VERSION "3.06 v1"

NS_ :

BS_:

BU_:

BO_ 3221225472 VECTOR__INDEPENDENT_SIG_MSG: 0 Vector__XXX
 SG_ EffectParametersRequest_Mux : 0|8@1+ (1,0) [0|0] "" Vector__XXX

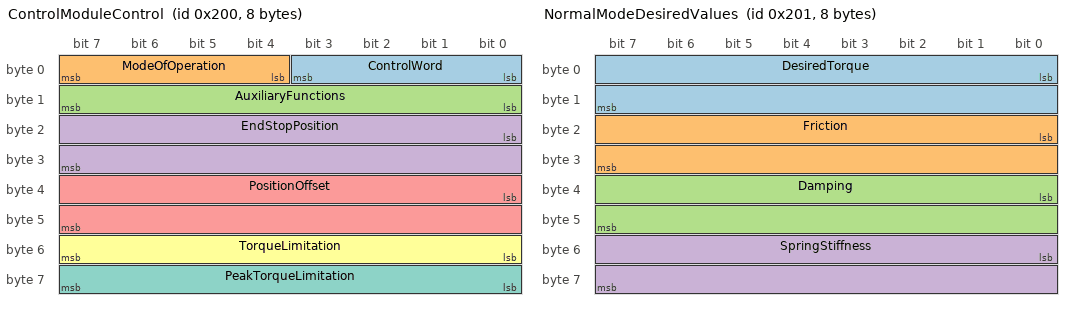
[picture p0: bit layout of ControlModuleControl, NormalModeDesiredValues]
BO_ 512 ControlModuleControl: 8 Vector__XXX
 SG_ ControlWord : 0|4@1+ (1,0) [0|15] "" Vector__XXX
 SG_ ModeOfOperation : 4|4@1+ (1,0) [1|8] "" Vector__XXX
 SG_ AuxiliaryFunctions : 8|8@1+ (1,0) [0|255] "" Vector__XXX
 SG_ EndStopPosition : 16|16@1+ (1,0) [0|1440] "°" Vector__XXX
 SG_ PositionOffset : 32|16@1- (1,0) [-359|359] "°" Vector__XXX
 SG_ TorqueLimitation : 48|8@1+ (1,0) [0|255] "%" Vector__XXX
 SG_ PeakTorqueLimitation : 56|8@1+ (1,0) [0|100] "%" Vector__XXX

BO_ 513 NormalModeDesiredValues: 8 Vector__XXX
 SG_ DesiredTorque : 0|16@1- (0.001,0) [-32.768|32.767] "Nm" Vector__XXX
 SG_ Friction : 16|16@1+ (1,0) [0|5000] "mNm" Vector__XXX
 SG_ Damping : 32|16@1+ (1,0) [0|500] "mNm/rpm" Vector__XXX
 SG_ SpringStiffness : 48|16@1+ (1,0) [0|2500] "mNm/°" Vector__XXX

BO_ 514 BasicModeDesiredValues: 2 Vector__XXX
 SG_ DesiredTorque : 0|16@1- (0.001,0) [-32.768|32.767] "Nm" Vector__XXX

BO_ 522 DigitalOutputValues: 2 Vector__XXX
 SG_ DigitalOutput : 0|3@1+ (1,0) [0|7] "" Vector__XXX

BO_ 523 AbsolutePosition: 2 Vector__XXX
 SG_ AbsolutePosition : 0|16@1- (0.1,0) [-1440|1440] "°" Vector__XXX

BO_ 557 SystemParametersRequest: 1 Vector__XXX
 SG_ SystemParametersRequest_Mux M : 0|8@1+ (1,0) [0|0] "" Vector__XXX

BO_ 525 ReadOnlyValuesRequest: 1 Vector__XXX
 SG_ ReadOnlyValuesRequest_Mux M : 0|8@1+ (1,0) [0|0] "" Vector__XXX

BO_ 526 VersionRequest: 1 Vector__XXX
 SG_ VersionRequest_Mux M : 0|8@1+ (1,0) [0|0] "" Vector__XXX

BO_ 554 EffectParametersWrite: 8 Vector__XXX
 SG_ EffectParametersWrite_Mux M : 0|8@1+ (1,0) [0|0] "" Vector__XXX
 SG_ EffParaDesEndStopStiffness m1 : 16|16@1+ (1,0) [0|255] "mNm/°" Vector__XXX
 SG_ EffParaDesEndStopDamping m1 : 32|16@1+ (1,0) [0|65535] "mNm/rpm" Vector__XXX
 SG_ EffParaDesReferencingDamping m2 : 16|16@1+ (1,0) [0|255] "mNm/rpm" Vector__XXX
 SG_ EffParaDesFrictionGain m3 : 16|16@1+ (1,0) [0|255] "" Vector__XXX
 SG_ EffParaDesFrictionEdge m3 : 32|16@1+ (1,0) [0|65535] "mNm" Vector__XXX
 SG_ EffParaDesEndStopVibrationDist m4 : 16|16@1+ (1,0) [0|255] "°" Vector__XXX
 SG_ EffParaDesEndStopVibrationPeriod m4 : 32|16@1+ (1,0) [0|65535] "ms" Vector__XXX
 SG_ EffParaDesEndStopVibrationGap m4 : 48|16@1+ (1,0) [0|65535] "ms" Vector__XXX
 SG_ EffParaDesFriction2Damping m5 : 16|16@1+ (1,0) [0|255] "mNm/°" Vector__XXX
 SG_ EffParaDesFriction2Factor m5 : 32|16@1+ (0.01,0) [0|655.35] "%" Vector__XXX
 SG_ EffParaDesDampingHalfDampingVel m6 : 16|16@1+ (0.1,0) [0|25.5] "rpm" Vector__XXX
 SG_ EffParaDesDampingVelFilterConst m6 : 32|16@1+ (1,0) [0|65535] "" Vector__XXX
 SG_ TorqueScaling m7 : 16|16@1+ (0.1,0) [0|0.1] "" Vector__XXX

BO_ 545 UserParametersRequest: 1 Vector__XXX
 SG_ UserParametersRequest_Mux M : 0|8@1+ (1,0) [0|0] "" Vector__XXX

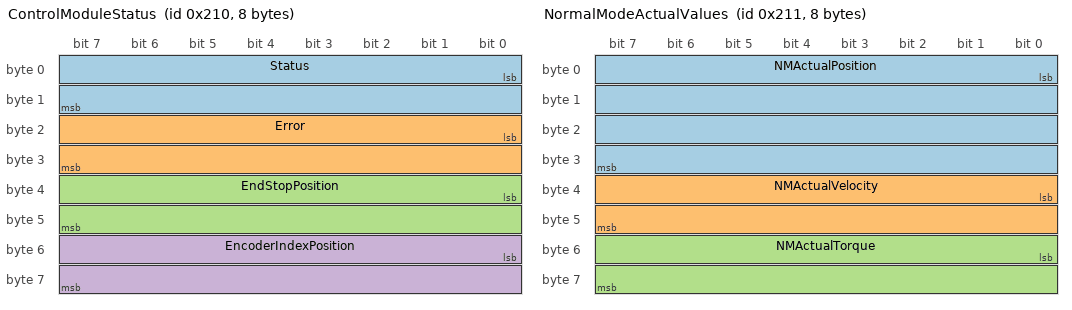
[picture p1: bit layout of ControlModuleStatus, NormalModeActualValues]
BO_ 528 ControlModuleStatus: 8 Vector__XXX
 SG_ Status : 0|16@1+ (1,0) [0|65535] "" Vector__XXX
 SG_ Error : 16|16@1+ (1,0) [0|65535] "" Vector__XXX
 SG_ EndStopPosition : 32|16@1+ (1,0) [0|1440] "°" Vector__XXX
 SG_ EncoderIndexPosition : 48|16@1- (1,0) [-359|359] "°" Vector__XXX

BO_ 529 NormalModeActualValues: 8 Vector__XXX
 SG_ NMActualPosition : 0|32@1- (1,0) [-2147483648|2147483647] "inc" Vector__XXX
 SG_ NMActualVelocity : 32|16@1- (1,0) [-32768|32767] "rpm" Vector__XXX
 SG_ NMActualTorque : 48|16@1- (0.001,0) [-32.768|32.767] "Nm" Vector__XXX

BO_ 530 BasicModeActualValues: 4 Vector__XXX
 SG_ BMActualPosition : 0|32@1- (1,0) [-2147483648|2147483647] "inc" Vector__XXX

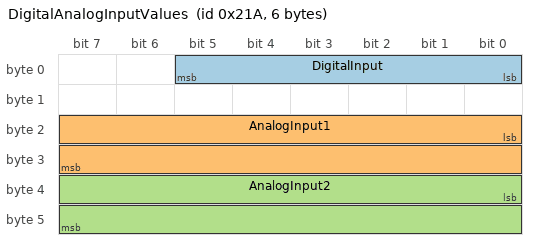
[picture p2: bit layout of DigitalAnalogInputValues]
BO_ 538 DigitalAnalogInputValues: 6 Vector__XXX
 SG_ DigitalInput : 0|6@1+ (1,0) [0|63] "" Vector__XXX
 SG_ AnalogInput1 : 16|16@1+ (1,0) [0|1023] "" Vector__XXX
 SG_ AnalogInput2 : 32|16@1+ (1,0) [0|1023] "" Vector__XXX

BO_ 539 AbsolutePositionResponse: 2 Vector__XXX
 SG_ AbsolutePosition : 0|16@1- (0.1,0) [-1440|1440] "°" Vector__XXX

BO_ 573 SystemParameters: 8 Vector__XXX
 SG_ SystemParameters_Mux M : 0|8@1+ (1,0) [0|0] "" Vector__XXX
 SG_ PositionIncrementsPerRevolution m1 : 16|32@1+ (1,0) [0|4294967295] "inc" Vector__XXX
 SG_ NominalTorque m2 : 16|16@1+ (0.001,0) [0|65.535] "Nm" Vector__XXX
 SG_ MaximumTorque m2 : 32|16@1+ (0.001,0) [0|65.535] "Nm" Vector__XXX

BO_ 541 ReadOnlyValues: 8 Vector__XXX
 SG_ ReadOnlyValues_Mux M : 0|8@1+ (1,0) [0|0] "" Vector__XXX
 SG_ TemperaturePowerStage m1 : 16|16@1+ (1,0) [0|65535] "°C" Vector__XXX
 SG_ TemperatureMicroprocessor m1 : 32|16@1+ (1,0) [0|65535] "°C" Vector__XXX
 SG_ TemperatureBreakChopper m1 : 48|16@1+ (1,0) [0|65535] "°C" Vector__XXX
 SG_ AverageAbsoluteMotorTorque m2 : 16|16@1+ (0.001,0) [0|65.535] "Nm" Vector__XXX
 SG_ Error m3 : 16|16@1+ (1,0) [0|65535] "" Vector__XXX
 SG_ HardwareSpecificError m3 : 32|16@1+ (1,0) [0|65535] "" Vector__XXX

BO_ 542 Version: 8 Vector__XXX
 SG_ Version_Mux M : 0|8@1+ (1,0) [0|0] "" Vector__XXX
 SG_ SoftwareBasicVersionMajor m1 : 24|8@1+ (1,0) [0|255] "" Vector__XXX
 SG_ SoftwareBasicVersionMinor m1 : 16|8@1+ (1,0) [0|255] "" Vector__XXX
 SG_ ProjectCode m1 : 32|16@1+ (1,0) [0|65535] "" Vector__XXX
 SG_ ProjectVersionMajor m1 : 56|8@1+ (1,0) [0|255] "" Vector__XXX
 SG_ ProjectVersionMinor m1 : 48|8@1+ (1,0) [0|255] "" Vector__XXX
 SG_ ProductCode m2 : 16|16@1+ (1,0) [0|65535] "" Vector__XXX
 SG_ HardwareOption m2 : 32|16@1+ (1,0) [0|65535] "" Vector__XXX

BO_ 570 EffectParameters: 8 Vector__XXX
 SG_ EffectParameters_Mux M : 0|8@1+ (1,0) [0|0] "" Vector__XXX
 SG_ EffParaEndStopStiffness m1 : 16|16@1+ (1,0) [0|65535] "mNm/°" Vector__XXX
 SG_ EffParaEndStopDamping m1 : 32|16@1+ (1,0) [0|65535] "mNm/rpm" Vector__XXX
 SG_ EffParaReferencingDamping m2 : 16|16@1+ (1,0) [0|65535] "mNm/rpm" Vector__XXX
 SG_ EffParaFrictionGain m3 : 16|16@1+ (1,0) [0|65535] "" Vector__XXX
 SG_ EffParaFrictionEdge m3 : 32|16@1+ (1,0) [0|65535] "mNm" Vector__XXX
 SG_ EffParaEndStopVibrationDist m4 : 16|16@1+ (1,0) [0|65535] "°" Vector__XXX
 SG_ EffParaEndStopVibrationPeriod m4 : 32|16@1+ (1,0) [0|65535] "ms" Vector__XXX
 SG_ EffParaEndStopVibrationGap m4 : 48|16@1+ (1,0) [0|65535] "ms" Vector__XXX
 SG_ EffParaFriction2Damping m5 : 16|16@1+ (1,0) [0|65535] "mNm/°" Vector__XXX
 SG_ EffParaFriction2Factor m5 : 32|16@1+ (0.01,0) [0|655.35] "%" Vector__XXX
 SG_ EffParaDampingHalfDampingVel m6 : 16|16@1+ (0.1,0) [0|6553.5] "rpm" Vector__XXX
 SG_ EffParaDampingVelFilterConst m6 : 32|16@1+ (1,0) [0|65535] "" Vector__XXX
 SG_ TorqueScaling m7 : 16|16@1+ (0.1,0) [10|100] "" Vector__XXX

BO_ 561 UserParameters: 8 Vector__XXX
 SG_ UserParameters_Mux M : 0|8@1+ (1,0) [0|0] "" Vector__XXX
 SG_ CANBaudRate : 16|32@1+ (1,0) [0|4294967295] "kBaud" Vector__XXX

CM_ BO_ 3221225472 "This is a message for not used signals, created by Vector CANdb++ DBC OLE DB Provider.";
CM_ BO_ 512 "Control Module ";
CM_ BO_ 513 "Normal Mode supporting full SENSO-Wheel features: Desired Values";
CM_ BO_ 514 "Basic Mode for fast communication: Desired Torque";
CM_ BO_ 522 "Digital output values (not SENSO-Wheel HT)";
CM_ BO_ 523 "Desired Absolute Position";
CM_ BO_ 557 "Request for System Parameters";
CM_ BO_ 525 "Request for Read-Only Values";
CM_ BO_ 526 "Request for Version and Product Information";
CM_ BO_ 554 "Write desired Effect ParametersRequest for Effect Parameters";
CM_ BO_ 545 "Request for User Parameters (firmware version 3.06 and newer)Write desired User Parameters (firmware version 3.06 and newer)";
CM_ BO_ 528 "Control Module";
CM_ BO_ 529 "Normal Mode supporting full SENSO-Wheel features: Actual Values";
CM_ BO_ 530 "Basic Mode for fast communication: Actual Position";
CM_ BO_ 538 "Digital and Analog Input Values (not SENSO-Wheel HT)";
CM_ BO_ 539 "Response to Desired Absolute Position";
CM_ BO_ 573 "System Parameters";
CM_ BO_ 541 "Read-Only Values";
CM_ BO_ 542 "Version and Product Information";
CM_ BO_ 570 "Effect Parameters";
CM_ BO_ 561 "User Parameters (firmware version 3.06 and newer)";
CM_ SG_ 561 UserParameters_Mux "CAN baud rate";
BA_DEF_  "BusType" STRING ;
BA_DEF_ BO_  "GenMsgCycleTime" INT 0 65535;
BA_DEF_ SG_  "GenSigStartValue" FLOAT -3.4E+038 3.4E+038;
BA_DEF_DEF_  "BusType" "CAN";
BA_DEF_DEF_  "GenMsgCycleTime" 0;
BA_DEF_DEF_  "GenSigStartValue" 0;
BA_ "GenMsgCycleTime" BO_ 512 10;
BA_ "GenMsgCycleTime" BO_ 513 1;
BA_ "GenMsgCycleTime" BO_ 514 1;
BA_ "GenSigStartValue" SG_ 512 ModeOfOperation 1;
BA_ "GenSigStartValue" SG_ 512 TorqueLimitation 100;
BA_ "GenSigStartValue" SG_ 512 PeakTorqueLimitation 100;
VAL_ 512 ControlWord 0 "SWITCH_OFF" 2 "SWITCH_READY" 4 "SWITCH_ON" 15 "QUIT_ERROR" ;
VAL_ 512 ModeOfOperation 1 "Normal Mode" 2 "Basic Mode" 4 "Referencing Mode" 8 "Demonstration Mode" ;
VAL_ 557 SystemParametersRequest_Mux 1 "DataSet1" 2 "DataSet2" ;
VAL_ 525 ReadOnlyValuesRequest_Mux 1 "DataSet1" 2 "DataSet2" 3 "DataSet3" ;
VAL_ 526 VersionRequest_Mux 1 "DataSet1" 2 "DataSet2" ;
VAL_ 554 EffectParametersWrite_Mux 1 "DataSet1" 2 "DataSet2" 3 "DataSet3" 4 "DataSet4" 5 "DataSet5" 6 "DataSet6" 7 "DataSet7" ;
VAL_ 545 UserParametersRequest_Mux 1 "Parameter1" ;
VAL_ 573 SystemParameters_Mux 1 "DataSet1" 2 "DataSet2" ;
VAL_ 541 ReadOnlyValues_Mux 1 "DataSet1" 2 "DataSet2" 3 "DataSet3" ;
VAL_ 542 Version_Mux 1 "DataSet1" 2 "DataSet2" ;
VAL_ 570 EffectParameters_Mux 1 "DataSet1" 2 "DataSet2" 3 "DataSet3" 4 "DataSet4" 5 "DataSet5" 6 "DataSet6" 7 "DataSet7" ;
VAL_ 561 UserParameters_Mux 1 "Parameter1" ;
VAL_ 561 CANBaudRate 250 "250" 500 "500" 1000 "1000" ;
